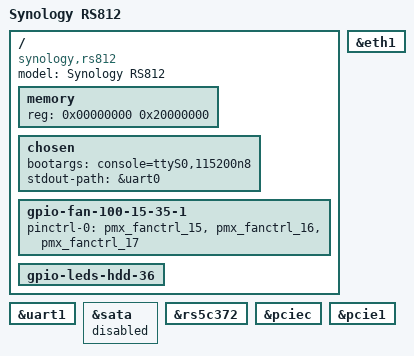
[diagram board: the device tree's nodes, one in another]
// SPDX-License-Identifier: GPL-2.0
/*
 * Synology RS812 (Marvell 88F6282, 512 MB, 4x SATA via PCIe 88SX7042, 2x GbE)
 * Based on kirkwood-rs411.dts ("RS411 RS812"), plus PCIe SATA like the DS411.
 * Internal SATA controller off: it would take mpp20/21, which eth1 (LAN 2) needs.
 * Fan: variant -1 without its alarm: on the RS812 mpp35 toggles with the fan (tach pulses), so the
 * "alarm" fired an IRQ + uevent per edge – udev never settled and boot waited 2 min. -3 clashes with mpp44.
 */
/dts-v1/;

#include "kirkwood.dtsi"
#include "kirkwood-6282.dtsi"
#include "kirkwood-synology.dtsi"

/ {
	model = "Synology RS812";
	compatible = "synology,rs812", "synology,rs411", "marvell,kirkwood";

	memory {
		device_type = "memory";
		reg = <0x00000000 0x20000000>;
	};

	chosen {
		bootargs = "console=ttyS0,115200n8";
		stdout-path = &uart0;
	};

	gpio-fan-100-15-35-1 {
		status = "okay";
		pinctrl-0 = <&pmx_fanctrl_15 &pmx_fanctrl_16 &pmx_fanctrl_17>;
		/delete-property/ alarm-gpios;
	};

	gpio-leds-hdd-36 {
		status = "okay";
	};
};

/* UART1 talks to the microcontroller (power/status LEDs, buzzer, power button), 9600 8N1, like under DSM */
&uart1 {
	status = "okay";
};

&eth1 {
	status = "okay";
};

&sata {
	status = "disabled";
};

/* the RS812 has a Ricoh RS5C372A at 0x32 (i2cdetect, DSM's synobios has rtc_ricoh_*), not the RS411's Seiko */
&rs5c372 {
	status = "okay";
};

&pciec {
	status = "okay";
};

&pcie1 {
	status = "okay";
};
